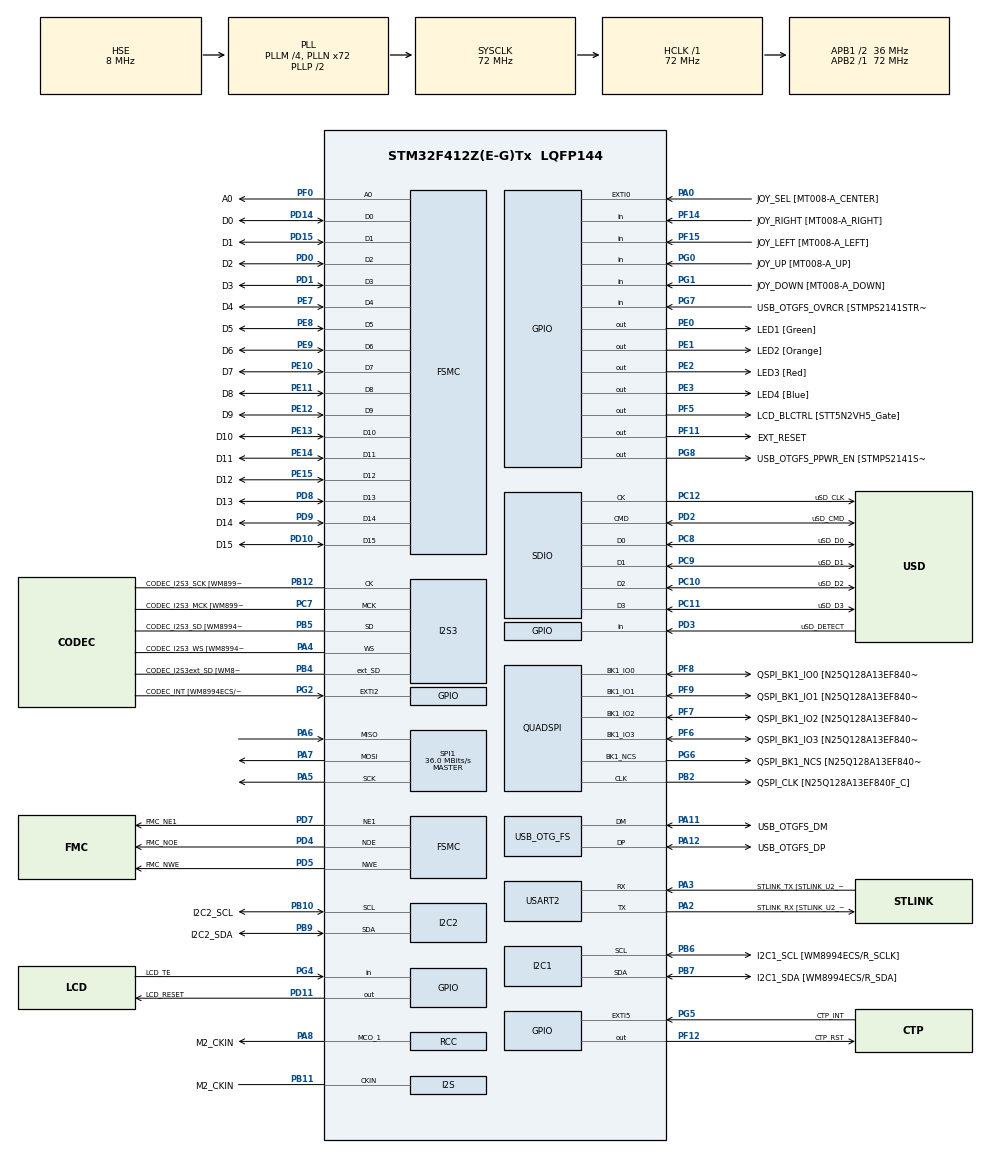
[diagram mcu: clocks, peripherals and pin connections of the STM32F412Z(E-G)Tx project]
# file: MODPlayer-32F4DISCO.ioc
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Dma.Request0=SPI3_TX
Dma.SPI3_TX.0.Direction=DMA_MEMORY_TO_PERIPH
Dma.SPI3_TX.0.FIFOMode=DMA_FIFOMODE_ENABLE
Dma.SPI3_TX.0.FIFOThreshold=DMA_FIFO_THRESHOLD_HALFFULL
Dma.SPI3_TX.0.Instance=DMA1_Stream5
Dma.SPI3_TX.0.MemBurst=DMA_MBURST_SINGLE
Dma.SPI3_TX.0.MemDataAlignment=DMA_MDATAALIGN_BYTE
Dma.SPI3_TX.0.MemInc=DMA_MINC_ENABLE
Dma.SPI3_TX.0.Mode=DMA_NORMAL
Dma.SPI3_TX.0.PeriphBurst=DMA_PBURST_SINGLE
Dma.SPI3_TX.0.PeriphDataAlignment=DMA_PDATAALIGN_BYTE
Dma.SPI3_TX.0.PeriphInc=DMA_PINC_DISABLE
Dma.SPI3_TX.0.Priority=DMA_PRIORITY_LOW
I2S3.AudioFreq=I2S_AUDIOFREQ_32K
I2S3.ErrorAudioFreq=1.72 %
I2S3.FullDuplexMode=I2S_FULLDUPLEXMODE_ENABLE
I2S3.Instance=SPI$Index
I2S3.RealAudioFreq=32.552 KHz
I2S3.VirtualMode=I2S_MODE_MASTER
Mcu.Family=STM32F4
Mcu.Name=STM32F412Z(E-G)Tx
Mcu.Package=LQFP144
NVIC.DMA1_Stream5_IRQn=true\:0\:0\:false\:false\:true\:false\:true
NVIC.OTG_FS_IRQn=true\:0\:0\:false\:false\:true\:true\:true
NVIC.PriorityGroup=NVIC_PRIORITYGROUP_4
PA0.GPIO_Label=JOY_SEL [MT008-A_CENTER]
PA0.Signal=GPXTI0
PA10.GPIO_Label=USB_OTGFS_ID
PA10.Signal=USB_OTG_FS_ID
PA11.GPIO_Label=USB_OTGFS_DM
PA11.Mode=Host_Only
PA11.Signal=USB_OTG_FS_DM
PA12.GPIO_Label=USB_OTGFS_DP
PA12.Mode=Host_Only
PA12.Signal=USB_OTG_FS_DP
PA13.GPIO_Label=SWDIO
PA13.Mode=Serial_Wire
PA13.Signal=SYS_JTMS-SWDIO
PA14.GPIO_Label=SWCLK
PA14.Mode=Serial_Wire
PA14.Signal=SYS_JTCK-SWCLK
PA2.GPIO_Label=STLINK_RX [STLINK_U2_RX]
PA2.Mode=Asynchronous
PA2.Signal=USART2_TX
PA3.GPIO_Label=STLINK_TX [STLINK_U2_TX]
PA3.Mode=Asynchronous
PA3.Signal=USART2_RX
PA4.GPIO_Label=CODEC_I2S3_WS [WM8994ECS/R_LRCLK1]
PA4.Mode=Full_Duplex_Master
PA4.Signal=I2S3_WS
PA5.Mode=Full_Duplex_Master
PA5.Signal=SPI1_SCK
PA6.Mode=Full_Duplex_Master
PA6.Signal=SPI1_MISO
PA7.Mode=Full_Duplex_Master
PA7.Signal=SPI1_MOSI
PA8.GPIO_Label=M2_CKIN
PA8.Mode=Clock-out-1
PA8.Signal=RCC_MCO_1
PA9.GPIO_Label=USB_OTGFS_VBUS
PA9.Signal=USB_OTG_FS_VBUS
PB1.GPIO_Label=DFSDM_DATIN0 [MP34DT01TR_DOUT]
PB1.Signal=S_DATAIN0DFSDM1
PB10.GPIO_Label=I2C2_SCL
PB10.Mode=I2C
PB10.Signal=I2C2_SCL
PB11.GPIO_Label=M2_CKIN
PB11.Mode=Audio_ClockIn
PB11.Signal=I2S_CKIN
PB12.GPIO_Label=CODEC_I2S3_SCK [WM8994ECS/R_BCLK1]
PB12.Mode=Full_Duplex_Master
PB12.Signal=I2S3_CK
PB2.GPIO_Label=QSPI_CLK [N25Q128A13EF840F_C]
PB2.Mode=Single Bank 1
PB2.Signal=QUADSPI_CLK
PB3.GPIO_Label=SWO
PB3.Signal=SYS_JTDO-SWO
PB4.GPIO_Label=CODEC_I2S3ext_SD [WM8994ECS/R_ACDAT1]
PB4.Mode=Full_Duplex_Master
PB4.Signal=I2S3_ext_SD
PB5.GPIO_Label=CODEC_I2S3_SD [WM8994ECS/R_DACDAT1]
PB5.Mode=Full_Duplex_Master
PB5.Signal=I2S3_SD
PB6.GPIO_Label=I2C1_SCL [WM8994ECS/R_SCLK]
PB6.Mode=I2C
PB6.Signal=I2C1_SCL
PB7.GPIO_Label=I2C1_SDA [WM8994ECS/R_SDA]
PB7.Mode=I2C
PB7.Signal=I2C1_SDA
PB9.GPIO_Label=I2C2_SDA
PB9.Mode=I2C
PB9.Signal=I2C2_SDA
PC10.GPIO_Label=uSD_D2
PC10.Mode=SD_4_bits_Wide_bus
PC10.Signal=SDIO_D2
PC11.GPIO_Label=uSD_D3
PC11.Mode=SD_4_bits_Wide_bus
PC11.Signal=SDIO_D3
PC12.GPIO_Label=uSD_CLK
PC12.Mode=SD_4_bits_Wide_bus
PC12.Signal=SDIO_CK
PC14-OSC32_IN.Mode=LSE-External-Oscillator
PC14-OSC32_IN.Signal=RCC_OSC32_IN
PC15-OSC32_OUT.Mode=LSE-External-Oscillator
PC15-OSC32_OUT.Signal=RCC_OSC32_OUT
PC2.GPIO_Label=DFSDM_CKOUT [MP34DT01TR_CLK]
PC2.Signal=S_CKOUTDFSDM1
PC7.GPIO_Label=CODEC_I2S3_MCK [WM8994ECS/R_MCLK1]
PC7.Mode=Master_Clock_Activated
PC7.Signal=I2S3_MCK
PC8.GPIO_Label=uSD_D0
PC8.Mode=SD_4_bits_Wide_bus
PC8.Signal=SDIO_D0
PC9.GPIO_Label=uSD_D1
PC9.Mode=SD_4_bits_Wide_bus
PC9.Signal=SDIO_D1
PD0.GPIO_Label=D2
PD0.Signal=FSMC_D2_DA2
PD1.GPIO_Label=D3
PD1.Signal=FSMC_D3_DA3
PD10.GPIO_Label=D15
PD10.Signal=FSMC_D15_DA15
PD11.GPIO_Label=LCD_RESET
PD11.Signal=GPIO_Output
PD14.GPIO_Label=D0
PD14.Signal=FSMC_D0_DA0
PD15.GPIO_Label=D1
PD15.Signal=FSMC_D1_DA1
PD2.GPIO_Label=uSD_CMD
PD2.Mode=SD_4_bits_Wide_bus
PD2.Signal=SDIO_CMD
PD3.GPIO_Label=uSD_DETECT
PD3.Signal=GPIO_Input
PD4.GPIO_Label=FMC_NOE
PD4.Signal=FSMC_NOE
PD5.GPIO_Label=FMC_NWE
PD5.Signal=FSMC_NWE
PD7.GPIO_Label=FMC_NE1
PD7.Mode=NorPsramChipSelect1_1
PD7.Signal=FSMC_NE1
PD8.GPIO_Label=D13
PD8.Signal=FSMC_D13_DA13
PD9.GPIO_Label=D14
PD9.Signal=FSMC_D14_DA14
PE0.GPIO_Label=LED1 [Green]
PE0.GPIO_ModeDefaultOutputPP=GPIO_MODE_OUTPUT_OD
PE0.Signal=GPIO_Output
PE1.GPIO_Label=LED2 [Orange]
PE1.GPIO_ModeDefaultOutputPP=GPIO_MODE_OUTPUT_OD
PE1.Signal=GPIO_Output
PE10.GPIO_Label=D7
PE10.Signal=FSMC_D7_DA7
PE11.GPIO_Label=D8
PE11.Signal=FSMC_D8_DA8
PE12.GPIO_Label=D9
PE12.Signal=FSMC_D9_DA9
PE13.GPIO_Label=D10
PE13.Signal=FSMC_D10_DA10
PE14.GPIO_Label=D11
PE14.Signal=FSMC_D11_DA11
PE15.GPIO_Label=D12
PE15.Signal=FSMC_D12_DA12
PE2.GPIO_Label=LED3 [Red]
PE2.GPIO_ModeDefaultOutputPP=GPIO_MODE_OUTPUT_OD
PE2.Signal=GPIO_Output
PE3.GPIO_Label=LED4 [Blue]
PE3.GPIO_ModeDefaultOutputPP=GPIO_MODE_OUTPUT_OD
PE3.Signal=GPIO_Output
PE4.GPIO_Label=DFSDM_DATIN3 [MP23DB01MM_DOUT]
PE4.Signal=S_DATAIN3DFSDM1
PE7.GPIO_Label=D4
PE7.Signal=FSMC_D4_DA4
PE8.GPIO_Label=D5
PE8.Signal=FSMC_D5_DA5
PE9.GPIO_Label=D6
PE9.Signal=FSMC_D6_DA6
PF0.GPIO_Label=A0
PF0.Signal=FSMC_A0
PF11.GPIO_Label=EXT_RESET
PF11.Signal=GPIO_Output
PF12.GPIO_Label=CTP_RST
PF12.Signal=GPIO_Output
PF14.GPIO_Label=JOY_RIGHT [MT008-A_RIGHT]
PF14.Signal=GPIO_Input
PF15.GPIO_Label=JOY_LEFT [MT008-A_LEFT]
PF15.Signal=GPIO_Input
PF5.GPIO_Label=LCD_BLCTRL [STT5N2VH5_Gate]
PF5.Signal=GPIO_Output
PF6.GPIO_Label=QSPI_BK1_IO3 [N25Q128A13EF840F_DQ3]
PF6.Mode=Single Bank 1
PF6.Signal=QUADSPI_BK1_IO3
PF7.GPIO_Label=QSPI_BK1_IO2 [N25Q128A13EF840F_DQ2]
PF7.Mode=Single Bank 1
PF7.Signal=QUADSPI_BK1_IO2
PF8.GPIO_Label=QSPI_BK1_IO0 [N25Q128A13EF840F_DQ0]
PF8.Mode=Single Bank 1
PF8.Signal=QUADSPI_BK1_IO0
PF9.GPIO_Label=QSPI_BK1_IO1 [N25Q128A13EF840F_DQ1]
PF9.Mode=Single Bank 1
PF9.Signal=QUADSPI_BK1_IO1
PG0.GPIO_Label=JOY_UP [MT008-A_UP]
PG0.Signal=GPIO_Input
PG1.GPIO_Label=JOY_DOWN [MT008-A_DOWN]
PG1.Signal=GPIO_Input
PG2.GPIO_Label=CODEC_INT [WM8994ECS/R_ADCLRCLK1/GPIO1]
PG2.Signal=GPXTI2
PG4.GPIO_Label=LCD_TE
PG4.Signal=GPIO_Input
PG5.GPIO_Label=CTP_INT
PG5.Signal=GPXTI5
PG6.GPIO_Label=QSPI_BK1_NCS [N25Q128A13EF840F_S]
PG6.Mode=Single Bank 1
PG6.Signal=QUADSPI_BK1_NCS
PG7.GPIO_Label=USB_OTGFS_OVRCR [STMPS2141STR_FAULT]
PG7.Signal=GPIO_Input
PG8.GPIO_Label=USB_OTGFS_PPWR_EN [STMPS2141STR_EN]
PG8.GPIO_ModeDefaultOutputPP=GPIO_MODE_OUTPUT_OD
PG8.PinState=GPIO_PIN_SET
PG8.Signal=GPIO_Output
PH0\ -\ OSC_IN.GPIO_Label=STLK_MCO
PH0\ -\ OSC_IN.Mode=HSE-External-Clock-Source
PH0\ -\ OSC_IN.Signal=RCC_OSC_IN
PH1\ -\ OSC_OUT.Mode=HSE-External-Clock-Source
PH1\ -\ OSC_OUT.Signal=RCC_OSC_OUT
ProjectManager.HeapSize=0x200
ProjectManager.StackSize=0x400
ProjectManager.TargetToolchain=Makefile
RCC.48MHZClocksFreq_Value=48000000
RCC.AHBFreq_Value=72000000
RCC.APB1CLKDivider=RCC_HCLK_DIV2
RCC.APB1Freq_Value=36000000
RCC.APB1TimFreq_Value=72000000
RCC.APB2Freq_Value=72000000
RCC.APB2TimFreq_Value=72000000
RCC.CortexFreq_Value=72000000
RCC.HCLKFreq_Value=72000000
RCC.HSE_VALUE=8000000
RCC.HSI_VALUE=16000000
RCC.PLLI2SM=4
RCC.PLLI2SN=50
RCC.PLLM=4
RCC.PLLN=72
RCC.PLLQ=3
RCC.SYSCLKFreq_VALUE=72000000
RCC.SYSCLKSource=RCC_SYSCLKSOURCE_PLLCLK
RCC.USBFreq_Value=48000000
RCC.VCOOutputFreq_Value=144000000
SDIO.WideMode=SDIO_BUS_WIDE_4B
SH.FSMC_A0.0=FSMC_A0,A0_1
SH.FSMC_D0_DA0.0=FSMC_D0,16b-d1
SH.FSMC_D10_DA10.0=FSMC_D10,16b-d1
SH.FSMC_D11_DA11.0=FSMC_D11,16b-d1
SH.FSMC_D12_DA12.0=FSMC_D12,16b-d1
SH.FSMC_D13_DA13.0=FSMC_D13,16b-d1
SH.FSMC_D14_DA14.0=FSMC_D14,16b-d1
SH.FSMC_D15_DA15.0=FSMC_D15,16b-d1
SH.FSMC_D1_DA1.0=FSMC_D1,16b-d1
SH.FSMC_D2_DA2.0=FSMC_D2,16b-d1
SH.FSMC_D3_DA3.0=FSMC_D3,16b-d1
SH.FSMC_D4_DA4.0=FSMC_D4,16b-d1
SH.FSMC_D5_DA5.0=FSMC_D5,16b-d1
SH.FSMC_D6_DA6.0=FSMC_D6,16b-d1
SH.FSMC_D7_DA7.0=FSMC_D7,16b-d1
SH.FSMC_D8_DA8.0=FSMC_D8,16b-d1
SH.FSMC_D9_DA9.0=FSMC_D9,16b-d1
SH.FSMC_NOE.0=FSMC_NOE,Lcd1
SH.FSMC_NWE.0=FSMC_NWE,Lcd1
SH.S_CKOUTDFSDM1.0=DFSDM1_CKOUT
SH.S_DATAIN0DFSDM1.0=DFSDM1_DATIN0
SH.S_DATAIN3DFSDM1.0=DFSDM1_DATIN3
SPI1.CalculateBaudRate=36.0 MBits/s
SPI1.Direction=SPI_DIRECTION_2LINES
SPI1.Mode=SPI_MODE_MASTER
SPI1.VirtualType=VM_MASTER
USART2.VirtualMode=VM_ASYNC
USB_HOST.BSP.number=1
USB_HOST.USBH_HandleTypeDef=hUsbHostFS
USB_HOST.VirtualModeFS=Cdc
USB_HOST0.BSP.STBoard=false
USB_HOST0.BSP.api=Unknown
USB_HOST0.BSP.i2caddr=0
USB_HOST0.BSP.i2creg=0
USB_HOST0.BSP.instance=PG8
USB_HOST0.BSP.ip=GPIO
USB_HOST0.BSP.mode=Output
USB_HOST0.BSP.name=Drive_VBUS_FS
USB_HOST0.BSP.solution=PG8
USB_OTG_FS.VirtualMode=Host_Only
USB_OTG_FS.phy_itface=HCD_PHY_EMBEDDED
VP_USB_HOST_VS_USB_HOST_CDC_FS.Mode=CDC_FS
board=STM32F412G-DISCO

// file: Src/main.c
/* USER CODE BEGIN Header */
/**
	******************************************************************************
	* @file           : main.c
	* @brief          : Main program body
	******************************************************************************
	* @attention
	*
	* <h2><center>&copy; Copyright (c) 2019 STMicroelectronics.
	* All rights reserved.</center></h2>
	*
	* This software component is licensed by ST under Ultimate Liberty license
	* SLA0044, the "License"; You may not use this file except in compliance with
	* the License. You may obtain a copy of the License at:
	*                             www.st.com/SLA0044
	*
	******************************************************************************
	*/
/* USER CODE END Header */

#include "main.h"
#include "usb_host.h"

/* USER CODE BEGIN PM */
#include "../Lib/HxCMOD/hxcmod.h"
#include "../../Drivers/DISCO/stm32412g_discovery_lcd.h"
#include "../../Drivers/DISCO/stm32412g_discovery_audio.h"
#include "../../Drivers/DISCO/stm32412g_discovery.h"
/* USER CODE END PM */

I2C_HandleTypeDef hi2c1;
I2C_HandleTypeDef hi2c2;

I2S_HandleTypeDef hi2s3;
DMA_HandleTypeDef hdma_spi3_tx;

QSPI_HandleTypeDef hqspi;

SD_HandleTypeDef hsd;

SPI_HandleTypeDef hspi1;

UART_HandleTypeDef huart2;

SRAM_HandleTypeDef hsram1;

/* USER CODE BEGIN PV */
#define LCD_SCREEN_WIDTH              240
#define LCD_SCREEN_HEIGHT             240
#define RGB565_BYTE_PER_PIXEL         2

#define PLAYER_SAMPLE_RATE 48000

// Mod player context
modcontext mcontext;

#define SAMPLE_BUFFER_SIZE 8192
msample dmasoundbuffer[SAMPLE_BUFFER_SIZE] __attribute__ ((aligned (4)));

extern const unsigned char mod_data[39424];

uint8_t uwInternelBuffer[LCD_SCREEN_WIDTH*LCD_SCREEN_HEIGHT*RGB565_BYTE_PER_PIXEL];

/* USER CODE END PV */

void SystemClock_Config(void);
static void MX_GPIO_Init(void);
static void MX_FSMC_Init(void);
static void MX_I2C1_Init(void);
static void MX_I2C2_Init(void);
static void MX_I2S3_Init(void);
static void MX_QUADSPI_Init(void);
static void MX_SDIO_SD_Init(void);
static void MX_USART2_UART_Init(void);
static void MX_SPI1_Init(void);
static void MX_DMA_Init(void);
void MX_USB_HOST_Process(void);

/* USER CODE BEGIN 0 */

BSP_AUDIO_OUT_HalfTransfer_CallBack(hi2s3){
	int i;
	/* Prevent unused argument(s) compilation warning */

	hxcmod_fillbuffer( &mcontext, (msample*)&dmasoundbuffer, SAMPLE_BUFFER_SIZE/2, NULL );

	// 16 to 12 bits conversion to match with the STM32 DAC.
	for(i=0;i<SAMPLE_BUFFER_SIZE/2;i++)
		dmasoundbuffer[i] = dmasoundbuffer[i] >> 4;
}

 BSP_AUDIO_OUT_TransferComplete_CallBack(){
	int i;

	hxcmod_fillbuffer( &mcontext, (msample*)&dmasoundbuffer[SAMPLE_BUFFER_SIZE/2], SAMPLE_BUFFER_SIZE/2, NULL );

	// 16 to 12 bits conversion to match with the STM32 DAC.
	for(i=0;i<SAMPLE_BUFFER_SIZE/2;i++)
		dmasoundbuffer[(SAMPLE_BUFFER_SIZE/2) + i] = dmasoundbuffer[(SAMPLE_BUFFER_SIZE/2) + i] >> 4;

}

/* USER CODE END 0 */

int main(void)
{

	/* MCU Configuration--------------------------------------------------------*/

	/* Reset of all peripherals, Initializes the Flash interface and the Systick. */
	HAL_Init();

	/* Configure the system clock */
	SystemClock_Config();

	/* Initialize all configured peripherals */
	MX_GPIO_Init();
	MX_FSMC_Init();
	MX_I2C1_Init();
	MX_I2C2_Init();
	MX_I2S3_Init();
	MX_QUADSPI_Init();
	MX_SDIO_SD_Init();
	MX_USART2_UART_Init();
	MX_USB_HOST_Init();
	MX_SPI1_Init();
	MX_DMA_Init();
	/* USER CODE BEGIN 2 */

	BSP_LED_Init(LED3);

	BSP_LCD_Init();

  /* Clear the LCD */
  BSP_LCD_Clear(LCD_COLOR_WHITE);

	BSP_AUDIO_OUT_Init(OUTPUT_DEVICE_HEADPHONE1, 64, I2S_AUDIOFREQ_48K);

	hxcmod_init( &mcontext );

	hxcmod_setcfg( &mcontext, PLAYER_SAMPLE_RATE, 0, 0);

  hxcmod_load( &mcontext, (void*)&mod_data, sizeof(mod_data) );
	int i;
	for(i=0;i<SAMPLE_BUFFER_SIZE;i++)
  {
    dmasoundbuffer[i] = 2048;
  }

	hxcmod_fillbuffer( &mcontext, (msample*)&dmasoundbuffer[SAMPLE_BUFFER_SIZE/2], SAMPLE_BUFFER_SIZE/2, NULL );

	HAL_I2S_Transmit_DMA(&hi2s3, (uint32_t*)&dmasoundbuffer, SAMPLE_BUFFER_SIZE);
	/* USER CODE END 2 */

	/* Infinite loop */
	while (1)
	{
	MX_USB_HOST_Process();

	}
}

void SystemClock_Config(void)
{
	RCC_OscInitTypeDef RCC_OscInitStruct = {0};
	RCC_ClkInitTypeDef RCC_ClkInitStruct = {0};
	RCC_PeriphCLKInitTypeDef PeriphClkInitStruct = {0};

	/** Configure the main internal regulator output voltage
	*/
	__HAL_RCC_PWR_CLK_ENABLE();
	__HAL_PWR_VOLTAGESCALING_CONFIG(PWR_REGULATOR_VOLTAGE_SCALE1);
	/** Initializes the CPU, AHB and APB busses clocks
	*/
	RCC_OscInitStruct.OscillatorType = RCC_OSCILLATORTYPE_HSI|RCC_OSCILLATORTYPE_HSE;
	RCC_OscInitStruct.HSEState = RCC_HSE_BYPASS;
	RCC_OscInitStruct.HSIState = RCC_HSI_ON;
	RCC_OscInitStruct.HSICalibrationValue = RCC_HSICALIBRATION_DEFAULT;
	RCC_OscInitStruct.PLL.PLLState = RCC_PLL_ON;
	RCC_OscInitStruct.PLL.PLLSource = RCC_PLLSOURCE_HSE;
	RCC_OscInitStruct.PLL.PLLM = 4;
	RCC_OscInitStruct.PLL.PLLN = 72;
	RCC_OscInitStruct.PLL.PLLP = RCC_PLLP_DIV2;
	RCC_OscInitStruct.PLL.PLLQ = 3;
	RCC_OscInitStruct.PLL.PLLR = 2;
	if (HAL_RCC_OscConfig(&RCC_OscInitStruct) != HAL_OK)
	{
	Error_Handler();
	}
	/** Initializes the CPU, AHB and APB busses clocks
	*/
	RCC_ClkInitStruct.ClockType = RCC_CLOCKTYPE_HCLK|RCC_CLOCKTYPE_SYSCLK
								|RCC_CLOCKTYPE_PCLK1|RCC_CLOCKTYPE_PCLK2;
	RCC_ClkInitStruct.SYSCLKSource = RCC_SYSCLKSOURCE_PLLCLK;
	RCC_ClkInitStruct.AHBCLKDivider = RCC_SYSCLK_DIV1;
	RCC_ClkInitStruct.APB1CLKDivider = RCC_HCLK_DIV2;
	RCC_ClkInitStruct.APB2CLKDivider = RCC_HCLK_DIV1;

	if (HAL_RCC_ClockConfig(&RCC_ClkInitStruct, FLASH_LATENCY_2) != HAL_OK)
	{
	Error_Handler();
	}
	PeriphClkInitStruct.PeriphClockSelection = RCC_PERIPHCLK_I2S_APB1|RCC_PERIPHCLK_SDIO
								|RCC_PERIPHCLK_CLK48;
	PeriphClkInitStruct.PLLI2S.PLLI2SN = 50;
	PeriphClkInitStruct.PLLI2S.PLLI2SM = 4;
	PeriphClkInitStruct.PLLI2S.PLLI2SR = 2;
	PeriphClkInitStruct.PLLI2S.PLLI2SQ = 2;
	PeriphClkInitStruct.Clk48ClockSelection = RCC_CLK48CLKSOURCE_PLLQ;
	PeriphClkInitStruct.SdioClockSelection = RCC_SDIOCLKSOURCE_CLK48;
	PeriphClkInitStruct.PLLI2SSelection = RCC_PLLI2SCLKSOURCE_PLLSRC;
	PeriphClkInitStruct.I2sApb1ClockSelection = RCC_I2SAPB1CLKSOURCE_PLLI2S;
	if (HAL_RCCEx_PeriphCLKConfig(&PeriphClkInitStruct) != HAL_OK)
	{
	Error_Handler();
	}
	HAL_RCC_MCOConfig(RCC_MCO1, RCC_MCO1SOURCE_HSI, RCC_MCODIV_1);
}

static void MX_I2C1_Init(void)
{

	hi2c1.Instance = I2C1;
	hi2c1.Init.ClockSpeed = 100000;
	hi2c1.Init.DutyCycle = I2C_DUTYCYCLE_2;
	hi2c1.Init.OwnAddress1 = 0;
	hi2c1.Init.AddressingMode = I2C_ADDRESSINGMODE_7BIT;
	hi2c1.Init.DualAddressMode = I2C_DUALADDRESS_DISABLE;
	hi2c1.Init.OwnAddress2 = 0;
	hi2c1.Init.GeneralCallMode = I2C_GENERALCALL_DISABLE;
	hi2c1.Init.NoStretchMode = I2C_NOSTRETCH_DISABLE;
	if (HAL_I2C_Init(&hi2c1) != HAL_OK)
	{
	Error_Handler();
	}

}

static void MX_I2C2_Init(void)
{

	hi2c2.Instance = I2C2;
	hi2c2.Init.ClockSpeed = 100000;
	hi2c2.Init.DutyCycle = I2C_DUTYCYCLE_2;
	hi2c2.Init.OwnAddress1 = 0;
	hi2c2.Init.AddressingMode = I2C_ADDRESSINGMODE_7BIT;
	hi2c2.Init.DualAddressMode = I2C_DUALADDRESS_DISABLE;
	hi2c2.Init.OwnAddress2 = 0;
	hi2c2.Init.GeneralCallMode = I2C_GENERALCALL_DISABLE;
	hi2c2.Init.NoStretchMode = I2C_NOSTRETCH_DISABLE;
	if (HAL_I2C_Init(&hi2c2) != HAL_OK)
	{
	Error_Handler();
	}

}

static void MX_I2S3_Init(void)
{

	hi2s3.Instance = SPI3;
	hi2s3.Init.Mode = I2S_MODE_MASTER_TX;
	hi2s3.Init.Standard = I2S_STANDARD_PHILIPS;
	hi2s3.Init.DataFormat = I2S_DATAFORMAT_16B;
	hi2s3.Init.MCLKOutput = I2S_MCLKOUTPUT_ENABLE;
	hi2s3.Init.AudioFreq = I2S_AUDIOFREQ_32K;
	hi2s3.Init.CPOL = I2S_CPOL_LOW;
	hi2s3.Init.ClockSource = I2S_CLOCK_PLL;
	hi2s3.Init.FullDuplexMode = I2S_FULLDUPLEXMODE_ENABLE;
	if (HAL_I2S_Init(&hi2s3) != HAL_OK)
	{
	Error_Handler();
	}

}

static void MX_QUADSPI_Init(void)
{

	/* QUADSPI parameter configuration*/
	hqspi.Instance = QUADSPI;
	hqspi.Init.ClockPrescaler = 255;
	hqspi.Init.FifoThreshold = 1;
	hqspi.Init.SampleShifting = QSPI_SAMPLE_SHIFTING_NONE;
	hqspi.Init.FlashSize = 1;
	hqspi.Init.ChipSelectHighTime = QSPI_CS_HIGH_TIME_1_CYCLE;
	hqspi.Init.ClockMode = QSPI_CLOCK_MODE_0;
	hqspi.Init.FlashID = QSPI_FLASH_ID_1;
	hqspi.Init.DualFlash = QSPI_DUALFLASH_DISABLE;
	if (HAL_QSPI_Init(&hqspi) != HAL_OK)
	{
	Error_Handler();
	}

}

static void MX_SDIO_SD_Init(void)
{

	hsd.Instance = SDIO;
	hsd.Init.ClockEdge = SDIO_CLOCK_EDGE_RISING;
	hsd.Init.ClockBypass = SDIO_CLOCK_BYPASS_DISABLE;
	hsd.Init.ClockPowerSave = SDIO_CLOCK_POWER_SAVE_DISABLE;
	hsd.Init.BusWide = SDIO_BUS_WIDE_1B;
	hsd.Init.HardwareFlowControl = SDIO_HARDWARE_FLOW_CONTROL_DISABLE;
	hsd.Init.ClockDiv = 0;
	if (HAL_SD_Init(&hsd) != HAL_OK)
	{
	Error_Handler();
	}
	if (HAL_SD_ConfigWideBusOperation(&hsd, SDIO_BUS_WIDE_4B) != HAL_OK)
	{
	Error_Handler();
	}

}

static void MX_SPI1_Init(void)
{

	/* SPI1 parameter configuration*/
	hspi1.Instance = SPI1;
	hspi1.Init.Mode = SPI_MODE_MASTER;
	hspi1.Init.Direction = SPI_DIRECTION_2LINES;
	hspi1.Init.DataSize = SPI_DATASIZE_8BIT;
	hspi1.Init.CLKPolarity = SPI_POLARITY_LOW;
	hspi1.Init.CLKPhase = SPI_PHASE_1EDGE;
	hspi1.Init.NSS = SPI_NSS_SOFT;
	hspi1.Init.BaudRatePrescaler = SPI_BAUDRATEPRESCALER_2;
	hspi1.Init.FirstBit = SPI_FIRSTBIT_MSB;
	hspi1.Init.TIMode = SPI_TIMODE_DISABLE;
	hspi1.Init.CRCCalculation = SPI_CRCCALCULATION_DISABLE;
	hspi1.Init.CRCPolynomial = 10;
	if (HAL_SPI_Init(&hspi1) != HAL_OK)
	{
	Error_Handler();
	}

}

static void MX_USART2_UART_Init(void)
{

	huart2.Instance = USART2;
	huart2.Init.BaudRate = 115200;
	huart2.Init.WordLength = UART_WORDLENGTH_8B;
	huart2.Init.StopBits = UART_STOPBITS_1;
	huart2.Init.Parity = UART_PARITY_NONE;
	huart2.Init.Mode = UART_MODE_TX_RX;
	huart2.Init.HwFlowCtl = UART_HWCONTROL_NONE;
	huart2.Init.OverSampling = UART_OVERSAMPLING_16;
	if (HAL_UART_Init(&huart2) != HAL_OK)
	{
	Error_Handler();
	}

}

static void MX_DMA_Init(void)
{

	/* DMA controller clock enable */
	__HAL_RCC_DMA1_CLK_ENABLE();

	/* DMA interrupt init */
	/* DMA1_Stream5_IRQn interrupt configuration */
	HAL_NVIC_SetPriority(DMA1_Stream5_IRQn, 0, 0);
	HAL_NVIC_EnableIRQ(DMA1_Stream5_IRQn);

}

static void MX_GPIO_Init(void)
{
	GPIO_InitTypeDef GPIO_InitStruct = {0};

	/* GPIO Ports Clock Enable */
	__HAL_RCC_GPIOE_CLK_ENABLE();
	__HAL_RCC_GPIOC_CLK_ENABLE();
	__HAL_RCC_GPIOF_CLK_ENABLE();
	__HAL_RCC_GPIOH_CLK_ENABLE();
	__HAL_RCC_GPIOA_CLK_ENABLE();
	__HAL_RCC_GPIOB_CLK_ENABLE();
	__HAL_RCC_GPIOG_CLK_ENABLE();
	__HAL_RCC_GPIOD_CLK_ENABLE();

	/*Configure GPIO pin Output Level */
	HAL_GPIO_WritePin(GPIOE, LED3_Pin|LED4_Pin|LED1_Pin|LED2_Pin, GPIO_PIN_RESET);

	/*Configure GPIO pin Output Level */
	HAL_GPIO_WritePin(GPIOF, LCD_BLCTRL_Pin|EXT_RESET_Pin|CTP_RST_Pin, GPIO_PIN_RESET);

	/*Configure GPIO pin Output Level */
	HAL_GPIO_WritePin(LCD_RESET_GPIO_Port, LCD_RESET_Pin, GPIO_PIN_RESET);

	/*Configure GPIO pin Output Level */
	HAL_GPIO_WritePin(USB_OTGFS_PPWR_EN_GPIO_Port, USB_OTGFS_PPWR_EN_Pin, GPIO_PIN_SET);

	/*Configure GPIO pins : LED3_Pin LED4_Pin LED1_Pin LED2_Pin */
	GPIO_InitStruct.Pin = LED3_Pin|LED4_Pin|LED1_Pin|LED2_Pin;
	GPIO_InitStruct.Mode = GPIO_MODE_OUTPUT_OD;
	GPIO_InitStruct.Pull = GPIO_NOPULL;
	GPIO_InitStruct.Speed = GPIO_SPEED_FREQ_LOW;
	HAL_GPIO_Init(GPIOE, &GPIO_InitStruct);

	/*Configure GPIO pin : DFSDM_DATIN3_Pin */
	GPIO_InitStruct.Pin = DFSDM_DATIN3_Pin;
	GPIO_InitStruct.Mode = GPIO_MODE_AF_PP;
	GPIO_InitStruct.Pull = GPIO_NOPULL;
	GPIO_InitStruct.Speed = GPIO_SPEED_FREQ_LOW;
	GPIO_InitStruct.Alternate = GPIO_AF8_DFSDM1;
	HAL_GPIO_Init(DFSDM_DATIN3_GPIO_Port, &GPIO_InitStruct);

	/*Configure GPIO pins : LCD_BLCTRL_Pin EXT_RESET_Pin CTP_RST_Pin */
	GPIO_InitStruct.Pin = LCD_BLCTRL_Pin|EXT_RESET_Pin|CTP_RST_Pin;
	GPIO_InitStruct.Mode = GPIO_MODE_OUTPUT_PP;
	GPIO_InitStruct.Pull = GPIO_NOPULL;
	GPIO_InitStruct.Speed = GPIO_SPEED_FREQ_LOW;
	HAL_GPIO_Init(GPIOF, &GPIO_InitStruct);

	/*Configure GPIO pin : DFSDM_CKOUT_Pin */
	GPIO_InitStruct.Pin = DFSDM_CKOUT_Pin;
	GPIO_InitStruct.Mode = GPIO_MODE_AF_PP;
	GPIO_InitStruct.Pull = GPIO_NOPULL;
	GPIO_InitStruct.Speed = GPIO_SPEED_FREQ_LOW;
	GPIO_InitStruct.Alternate = GPIO_AF8_DFSDM1;
	HAL_GPIO_Init(DFSDM_CKOUT_GPIO_Port, &GPIO_InitStruct);

	/*Configure GPIO pin : JOY_SEL_Pin */
	GPIO_InitStruct.Pin = JOY_SEL_Pin;
	GPIO_InitStruct.Mode = GPIO_MODE_IT_RISING;
	GPIO_InitStruct.Pull = GPIO_NOPULL;
	HAL_GPIO_Init(JOY_SEL_GPIO_Port, &GPIO_InitStruct);

	/*Configure GPIO pin : DFSDM_DATIN0_Pin */
	GPIO_InitStruct.Pin = DFSDM_DATIN0_Pin;
	GPIO_InitStruct.Mode = GPIO_MODE_AF_PP;
	GPIO_InitStruct.Pull = GPIO_NOPULL;
	GPIO_InitStruct.Speed = GPIO_SPEED_FREQ_LOW;
	GPIO_InitStruct.Alternate = GPIO_AF8_DFSDM1;
	HAL_GPIO_Init(DFSDM_DATIN0_GPIO_Port, &GPIO_InitStruct);

	/*Configure GPIO pins : JOY_RIGHT_Pin JOY_LEFT_Pin */
	GPIO_InitStruct.Pin = JOY_RIGHT_Pin|JOY_LEFT_Pin;
	GPIO_InitStruct.Mode = GPIO_MODE_INPUT;
	GPIO_InitStruct.Pull = GPIO_NOPULL;
	HAL_GPIO_Init(GPIOF, &GPIO_InitStruct);

	/*Configure GPIO pins : JOY_UP_Pin JOY_DOWN_Pin LCD_TE_Pin USB_OTGFS_OVRCR_Pin */
	GPIO_InitStruct.Pin = JOY_UP_Pin|JOY_DOWN_Pin|LCD_TE_Pin|USB_OTGFS_OVRCR_Pin;
	GPIO_InitStruct.Mode = GPIO_MODE_INPUT;
	GPIO_InitStruct.Pull = GPIO_NOPULL;
	HAL_GPIO_Init(GPIOG, &GPIO_InitStruct);

	/*Configure GPIO pin : M2_CKIN_Pin */
	GPIO_InitStruct.Pin = M2_CKIN_Pin;
	GPIO_InitStruct.Mode = GPIO_MODE_AF_PP;
	GPIO_InitStruct.Pull = GPIO_NOPULL;
	GPIO_InitStruct.Speed = GPIO_SPEED_FREQ_LOW;
	GPIO_InitStruct.Alternate = GPIO_AF5_SPI1;
	HAL_GPIO_Init(M2_CKIN_GPIO_Port, &GPIO_InitStruct);

	/*Configure GPIO pin : LCD_RESET_Pin */
	GPIO_InitStruct.Pin = LCD_RESET_Pin;
	GPIO_InitStruct.Mode = GPIO_MODE_OUTPUT_PP;
	GPIO_InitStruct.Pull = GPIO_NOPULL;
	GPIO_InitStruct.Speed = GPIO_SPEED_FREQ_LOW;
	HAL_GPIO_Init(LCD_RESET_GPIO_Port, &GPIO_InitStruct);

	/*Configure GPIO pins : CODEC_INT_Pin CTP_INT_Pin */
	GPIO_InitStruct.Pin = CODEC_INT_Pin|CTP_INT_Pin;
	GPIO_InitStruct.Mode = GPIO_MODE_IT_RISING;
	GPIO_InitStruct.Pull = GPIO_NOPULL;
	HAL_GPIO_Init(GPIOG, &GPIO_InitStruct);

	/*Configure GPIO pin : USB_OTGFS_PPWR_EN_Pin */
	GPIO_InitStruct.Pin = USB_OTGFS_PPWR_EN_Pin;
	GPIO_InitStruct.Mode = GPIO_MODE_OUTPUT_OD;
	GPIO_InitStruct.Pull = GPIO_NOPULL;
	GPIO_InitStruct.Speed = GPIO_SPEED_FREQ_LOW;
	HAL_GPIO_Init(USB_OTGFS_PPWR_EN_GPIO_Port, &GPIO_InitStruct);

	/*Configure GPIO pin : M2_CKINA8_Pin */
	GPIO_InitStruct.Pin = M2_CKINA8_Pin;
	GPIO_InitStruct.Mode = GPIO_MODE_AF_PP;
	GPIO_InitStruct.Pull = GPIO_NOPULL;
	GPIO_InitStruct.Speed = GPIO_SPEED_FREQ_LOW;
	GPIO_InitStruct.Alternate = GPIO_AF0_MCO;
	HAL_GPIO_Init(M2_CKINA8_GPIO_Port, &GPIO_InitStruct);

	/*Configure GPIO pin : uSD_DETECT_Pin */
	GPIO_InitStruct.Pin = uSD_DETECT_Pin;
	GPIO_InitStruct.Mode = GPIO_MODE_INPUT;
	GPIO_InitStruct.Pull = GPIO_NOPULL;
	HAL_GPIO_Init(uSD_DETECT_GPIO_Port, &GPIO_InitStruct);

}

/* FSMC initialization function */
static void MX_FSMC_Init(void)
{

	FSMC_NORSRAM_TimingTypeDef Timing = {0};

	/** Perform the SRAM1 memory initialization sequence
	*/
	hsram1.Instance = FSMC_NORSRAM_DEVICE;
	hsram1.Extended = FSMC_NORSRAM_EXTENDED_DEVICE;
	/* hsram1.Init */
	hsram1.Init.NSBank = FSMC_NORSRAM_BANK1;
	hsram1.Init.DataAddressMux = FSMC_DATA_ADDRESS_MUX_DISABLE;
	hsram1.Init.MemoryType = FSMC_MEMORY_TYPE_SRAM;
	hsram1.Init.MemoryDataWidth = FSMC_NORSRAM_MEM_BUS_WIDTH_16;
	hsram1.Init.BurstAccessMode = FSMC_BURST_ACCESS_MODE_DISABLE;
	hsram1.Init.WaitSignalPolarity = FSMC_WAIT_SIGNAL_POLARITY_LOW;
	hsram1.Init.WaitSignalActive = FSMC_WAIT_TIMING_BEFORE_WS;
	hsram1.Init.WriteOperation = FSMC_WRITE_OPERATION_ENABLE;
	hsram1.Init.WaitSignal = FSMC_WAIT_SIGNAL_DISABLE;
	hsram1.Init.ExtendedMode = FSMC_EXTENDED_MODE_DISABLE;
	hsram1.Init.AsynchronousWait = FSMC_ASYNCHRONOUS_WAIT_DISABLE;
	hsram1.Init.WriteBurst = FSMC_WRITE_BURST_DISABLE;
	hsram1.Init.ContinuousClock = FSMC_CONTINUOUS_CLOCK_SYNC_ONLY;
	hsram1.Init.WriteFifo = FSMC_WRITE_FIFO_ENABLE;
	hsram1.Init.PageSize = FSMC_PAGE_SIZE_NONE;
	/* Timing */
	Timing.AddressSetupTime = 15;
	Timing.AddressHoldTime = 15;
	Timing.DataSetupTime = 255;
	Timing.BusTurnAroundDuration = 15;
	Timing.CLKDivision = 16;
	Timing.DataLatency = 17;
	Timing.AccessMode = FSMC_ACCESS_MODE_A;
	/* ExtTiming */

	if (HAL_SRAM_Init(&hsram1, &Timing, NULL) != HAL_OK)
	{
	Error_Handler( );
	}

}

void Error_Handler(void)
{
}

/************************ (C) COPYRIGHT STMicroelectronics *****END OF FILE****/
